AUTOSAR XML (schema 4-3-0)
package /Impl_ARPkg
  swc implementation Impl_SWC_APP_type: programming-language=C, sw-version=1.0.0, vendor-id=0, behavior=SWC_APP_type_IB
    code-descriptors:
      code SRC: artifact-descriptors=autosar-engineering-object={short-label=EngObject, category=SWSRC}
    resource consumption ResourceConsumption
      memory section MEM_SWC_APP_CODE: size=0, sw-addrmethod=CODE, symbol=CODE
      memory section MEM_SWC_APP_CAL: size=0, sw-addrmethod=CAL, symbol=CAL
package /SWC_APP_ARPkg
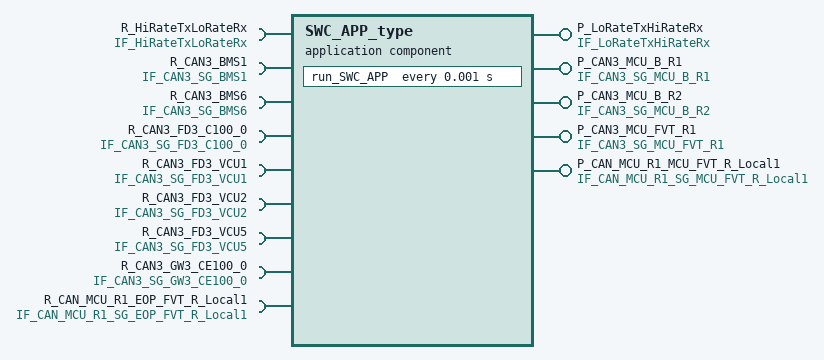
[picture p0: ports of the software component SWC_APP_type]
  application sw component type SWC_APP_type
    5 x provide port:
      P_LoRateTxHiRateRx: provided-interface=IF_LoRateTxHiRateRx
      P_CAN3_MCU_B_R1: provided-interface=IF_CAN3_SG_MCU_B_R1
      P_CAN3_MCU_B_R2: provided-interface=IF_CAN3_SG_MCU_B_R2
      P_CAN3_MCU_FVT_R1: provided-interface=IF_CAN3_SG_MCU_FVT_R1
      P_CAN_MCU_R1_MCU_FVT_R_Local1: provided-interface=IF_CAN_MCU_R1_SG_MCU_FVT_R_Local1
    9 x require port:
      R_HiRateTxLoRateRx: required-interface=IF_HiRateTxLoRateRx
      R_CAN3_BMS1: required-interface=IF_CAN3_SG_BMS1
      R_CAN3_BMS6: required-interface=IF_CAN3_SG_BMS6
      R_CAN3_FD3_C100_0: required-interface=IF_CAN3_SG_FD3_C100_0
      R_CAN3_FD3_VCU1: required-interface=IF_CAN3_SG_FD3_VCU1
      R_CAN3_FD3_VCU2: required-interface=IF_CAN3_SG_FD3_VCU2
      R_CAN3_FD3_VCU5: required-interface=IF_CAN3_SG_FD3_VCU5
      R_CAN3_GW3_CE100_0: required-interface=IF_CAN3_SG_GW3_CE100_0
      R_CAN_MCU_R1_EOP_FVT_R_Local1: required-interface=IF_CAN_MCU_R1_SG_EOP_FVT_R_Local1
    behavior SWC_APP_type_IB: handle-termination-and-restart=NO-SUPPORT
      timing event TE_1ms: start-on-event=run_SWC_APP, period=0.001
      runnable run_SWC_APP
        data-receive-point-by-arguments:
          9 x access:
            drparg_HiRateTxLoRateRx: accessed-variable=R_HiRateTxLoRateRx.HiRateTxLoRateRx
            drparg_CAN3_SG_BMS1: accessed-variable=R_CAN3_BMS1.CAN3_SG_BMS1
            drparg_CAN3_SG_BMS6: accessed-variable=R_CAN3_BMS6.CAN3_SG_BMS6
            drparg_CAN3_SG_FD3_C100_0: accessed-variable=R_CAN3_FD3_C100_0.CAN3_SG_FD3_C100_0
            drparg_CAN3_SG_FD3_VCU1: accessed-variable=R_CAN3_FD3_VCU1.CAN3_SG_FD3_VCU1
            drparg_CAN3_SG_FD3_VCU2: accessed-variable=R_CAN3_FD3_VCU2.CAN3_SG_FD3_VCU2
            drparg_CAN3_SG_FD3_VCU5: accessed-variable=R_CAN3_FD3_VCU5.CAN3_SG_FD3_VCU5
            drparg_CAN3_SG_GW3_CE100_0: accessed-variable=R_CAN3_GW3_CE100_0.CAN3_SG_GW3_CE100_0
            drparg_CAN_MCU_R1_SG_EOP_FVT_R_Local1: accessed-variable=R_CAN_MCU_R1_EOP_FVT_R_Local1.CAN_MCU_R1_SG_EOP_FVT_R_Local1
        data-send-points:
          5 x access:
            dsp_LoRateTxHiRateRx: accessed-variable=P_LoRateTxHiRateRx.LoRateTxHiRateRx
            dsp_CAN3_SG_MCU_B_R1: accessed-variable=P_CAN3_MCU_B_R1.CAN3_SG_MCU_B_R1
            dsp_CAN3_SG_MCU_B_R2: accessed-variable=P_CAN3_MCU_B_R2.CAN3_SG_MCU_B_R2
            dsp_CAN3_SG_MCU_FVT_R1: accessed-variable=P_CAN3_MCU_FVT_R1.CAN3_SG_MCU_FVT_R1
            dsp_CAN_MCU_R1_SG_MCU_FVT_R_Local1: accessed-variable=P_CAN_MCU_R1_MCU_FVT_R_Local1.CAN_MCU_R1_SG_MCU_FVT_R_Local1
